# WS63 register map
File version: 1.0
CPU: other r0p0, little endian, MPU, FPU, 3 interrupt priority bits
Registers are 32-bit, read-write, reset 0x0 unless marked. A register's access mark holds for its fields unless they carry their own. Offsets are from the block's base; [hi:lo] are bit positions.

## SPI0 — SPI0 master/slave controller (SSI v151)
Base 0x44020000
Same registers: SPI1 0x44021000
0x00 SPI_ER — SPI enable register
  [0] spi_en — SPI enable: 0=disabled; 1=enabled
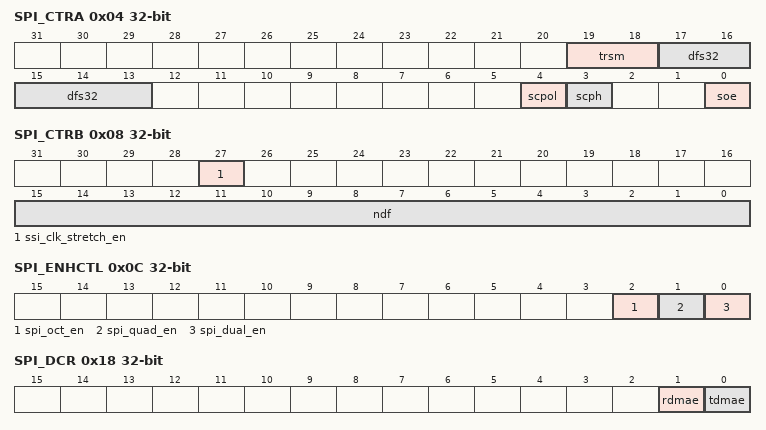
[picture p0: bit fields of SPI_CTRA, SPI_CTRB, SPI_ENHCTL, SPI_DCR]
0x04 SPI_CTRA — SPI control register 0
  [19:18] trsm — Transfer mode: 00=TX/RX; 01=TX only; 10=RX only
    0=TxRx (Transmit and Receive); 1=TxOnly (Transmit Only); 2=RxOnly (Receive Only)
  [17:13] dfs32 — Data frame size in 32-bit mode (0=4bit; up to 31=35bit)
  [4] scpol — Clock polarity: 0=low idle; 1=high idle
    0=LowIdle (SCK idle low); 1=HighIdle (SCK idle high)
  [3] scph — Clock phase: 0=first edge sample; 1=second edge sample
    0=FirstEdge (Sample on first clock edge); 1=SecondEdge (Sample on second clock edge)
  [0] soe — Shift register loop test: 0=normal; 1=loopback
0x08 SPI_CTRB — SPI control register 1 (master only)
  [27] ssi_clk_stretch_en — Clock stretch enable
  [15:0] ndf — Number of data frames (master TX only mode)
0x0C SPI_ENHCTL — Enhanced control register (Dual/Quad/Octal)
  [2] spi_oct_en — Octal SPI mode enable
  [1] spi_quad_en — Quad SPI mode enable
  [0] spi_dual_en — Dual SPI mode enable
0x14 SPI_BRS — Baud rate select register
  [15:0] clk_div — Clock divider (master): SCK = SSI_CLK / (2 * (1 + CLK_DIV))
0x18 SPI_DCR — DMA control register
  [1] rdmae — RX DMA enable
  [0] tdmae — TX DMA enable
0x1C SPI_DRDL — DMA RX data level
  [7:0] dma_rx_data_level — DMA RX FIFO threshold
0x20 SPI_DTDL — DMA TX data level
  [7:0] dma_tx_data_level — DMA TX FIFO threshold
0x60 SPI_DR — Data register (FIFO read/write)
  [31:0] dr — Write: push to TX FIFO; Read: pop from RX FIFO
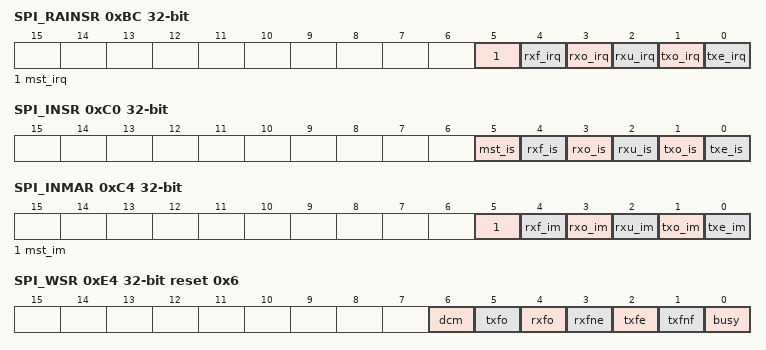
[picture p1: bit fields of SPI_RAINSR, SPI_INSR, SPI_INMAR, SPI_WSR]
0xBC SPI_RAINSR — Raw interrupt status register
  [5] mst_irq ro — Multi-master contention raw status
  [4] rxf_irq ro — RX FIFO full raw status
  [3] rxo_irq ro — RX FIFO overflow raw status
  [2] rxu_irq ro — RX FIFO underflow raw status
  [1] txo_irq ro — TX FIFO overflow raw status
  [0] txe_irq ro — TX FIFO empty raw status
0xC0 SPI_INSR — Interrupt status register (masked)
  [5] mst_is ro — Multi-master interrupt status
  [4] rxf_is ro — RX full interrupt status
  [3] rxo_is ro — RX overflow interrupt status
  [2] rxu_is ro — RX underflow interrupt status
  [1] txo_is ro — TX overflow interrupt status
  [0] txe_is ro — TX empty interrupt status
0xC4 SPI_INMAR — Interrupt mask register
  [5] mst_im — Multi-master interrupt mask
  [4] rxf_im — RX full interrupt mask
  [3] rxo_im — RX overflow interrupt mask
  [2] rxu_im — RX underflow interrupt mask
  [1] txo_im — TX overflow interrupt mask
  [0] txe_im — TX empty interrupt mask
0xC8 SPI_SLENR — Slave enable register (master only)
  [0] slave_enable — Slave select enable
0xCC SPI_TWLR — TX FIFO threshold level
  [7:0] tx_fifo_threshold
0xD0 SPI_TLR — TX FIFO level register
  [7:0] tx_fifo_level ro — TX FIFO data level
0xD8 SPI_RWLR — RX FIFO threshold level
  [7:0] rx_fifo_threshold
0xDC SPI_RLR — RX FIFO level register
  [7:0] rx_fifo_level ro — RX FIFO data level
0xE4 SPI_WSR reset 0x6 — Status register
  [6] dcm ro — Data conflict mask
  [5] txfo ro — TX FIFO overflow
  [4] rxfo ro — RX FIFO overflow
  [3] rxfne ro — RX FIFO not empty
  [2] txfe ro — TX FIFO empty
  [1] txfnf ro — TX FIFO not full
  [0] busy ro — SPI busy flag
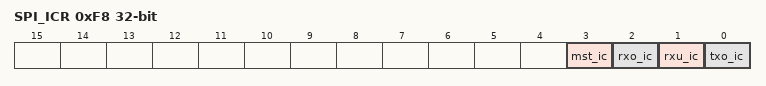
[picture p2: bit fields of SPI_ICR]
0xF8 SPI_ICR — Interrupt clear register
  [3] mst_ic wo — Multi-master interrupt clear
  [2] rxo_ic wo — RX overflow interrupt clear
  [1] rxu_ic wo — RX underflow interrupt clear
  [0] txo_ic wo — TX overflow interrupt clear

## I2S — I2S/SIO synchronous audio interface (v151)
Base 0x44025000
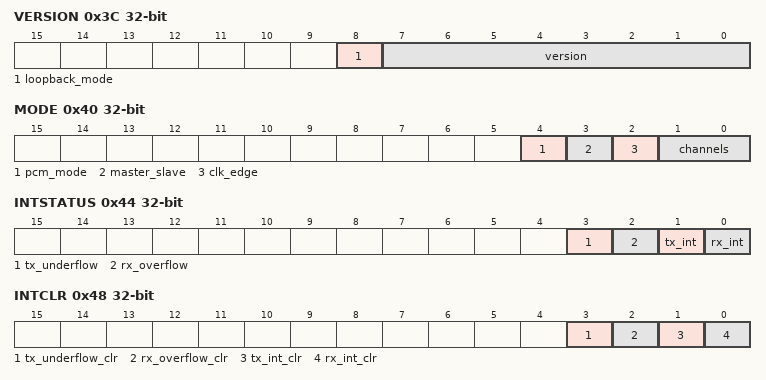
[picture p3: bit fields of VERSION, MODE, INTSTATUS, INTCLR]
0x3C VERSION — Version and loopback register
  [8] loopback_mode — Loopback mode enable
  [7:0] version ro — IP version
0x40 MODE — I2S/PCM mode register
  [4] pcm_mode — PCM mode: 0=I2S; 1=PCM
  [3] master_slave — Mode: 0=slave; 1=master
  [2] clk_edge — Clock edge: 0=rising; 1=falling
  [1:0] channels — Number of channels: 0=2ch; 1=4ch; 2=6ch; 3=8ch
0x44 INTSTATUS — Interrupt status register
  [3] tx_underflow ro — TX underflow status
  [2] rx_overflow ro — RX overflow status
  [1] tx_int ro — TX interrupt status
  [0] rx_int ro — RX interrupt status
0x48 INTCLR — Interrupt clear register
  [3] tx_underflow_clr wo — Clear TX underflow
  [2] rx_overflow_clr wo — Clear RX overflow
  [1] tx_int_clr wo — Clear TX interrupt
  [0] rx_int_clr wo — Clear RX interrupt
0x4C LEFT_TX — TX left channel data
  [31:0] left_tx_data
0x50 RIGHT_TX — TX right channel data
  [31:0] right_tx_data
0x54 LEFT_RX — RX left channel data
  [31:0] left_rx_data ro
0x58 RIGHT_RX — RX right channel data
  [31:0] right_rx_data ro
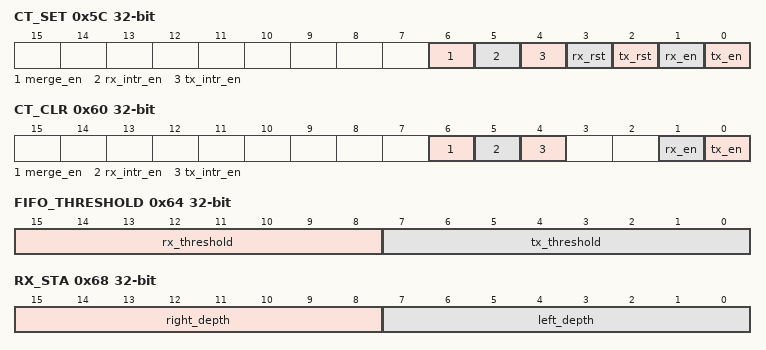
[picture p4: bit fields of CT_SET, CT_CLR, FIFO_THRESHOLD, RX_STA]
0x5C CT_SET — Control set register
  [6] merge_en wo — Merge enable set
  [5] rx_intr_en wo — RX interrupt enable set
  [4] tx_intr_en wo — TX interrupt enable set
  [3] rx_rst wo — RX reset set
  [2] tx_rst wo — TX reset set
  [1] rx_en wo — RX enable set
  [0] tx_en wo — TX enable set
0x60 CT_CLR — Control clear register
  [6] merge_en wo — Merge disable
  [5] rx_intr_en wo — RX interrupt disable
  [4] tx_intr_en wo — TX interrupt disable
  [1] rx_en wo — RX enable clear
  [0] tx_en wo — TX enable clear
0x64 FIFO_THRESHOLD
  [15:8] rx_threshold — RX FIFO threshold
  [7:0] tx_threshold — TX FIFO threshold
0x68 RX_STA — RX status register
  [15:8] right_depth ro — RX right FIFO depth
  [7:0] left_depth ro — RX left FIFO depth
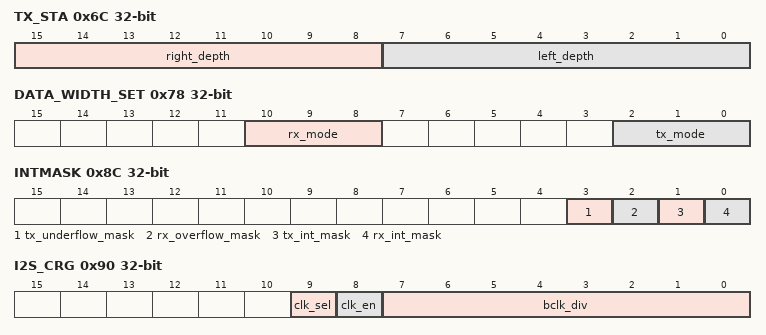
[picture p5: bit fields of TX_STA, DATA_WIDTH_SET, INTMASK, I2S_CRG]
0x6C TX_STA — TX status register
  [15:8] right_depth ro — TX right FIFO depth
  [7:0] left_depth ro — TX left FIFO depth
0x78 DATA_WIDTH_SET — Data width register
  [10:8] rx_mode — RX data width mode
  [2:0] tx_mode — TX data width mode
0x84 SIGNED_EXT — Signed extension enable
  [0] signed_ext_en
0x8C INTMASK — Interrupt mask register
  [3] tx_underflow_mask
  [2] rx_overflow_mask
  [1] tx_int_mask — TX interrupt mask
  [0] rx_int_mask — RX interrupt mask
0x90 I2S_CRG — I2S clock/reset generator
  [9] clk_sel — Clock source select
  [8] clk_en — Clock enable
  [7:0] bclk_div — BCLK divider
0x94 I2S_BCLK_DIV_NUM — BCLK divider number
  [6:0] bclk_div_num
0x98 I2S_FS_DIV_NUM — FS divider number
  [9:0] fs_div_num
0x9C I2S_FS_DIV_RATIO_NUM — FS divider ratio number
  [10:0] fs_div_ratio_num
